VERSION "DNNBNNNYNNNNNNNNNNNNNNNNNNYYYNNNNNNNNNNNNN/4/%%%/4/'%**4NNN///"

NS_ :

BS_:

BU_: Hacker Engine Display Light

BO_ 3221225472 VECTOR__INDEPENDENT_SIG_MSG: 0 Vector__XXX
 SG_ ECUName : 0|8@1- (1,0) [0|0] "" Vector__XXX
 SG_ PrivateChallenge : 0|16@1+ (1,0) [0|0] "" Vector__XXX

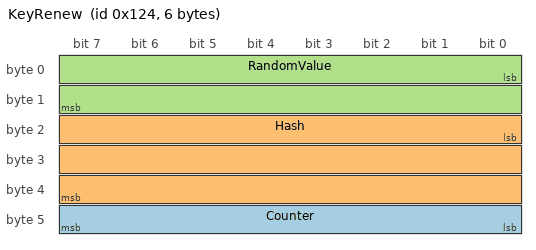
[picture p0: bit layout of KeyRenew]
BO_ 292 KeyRenew: 6 Vector__XXX
 SG_ Counter : 40|8@1+ (1,0) [0|0] "" Vector__XXX
 SG_ Hash : 16|24@1+ (1,0) [0|0] "" Vector__XXX
 SG_ RandomValue : 0|16@1+ (1,0) [0|0] "" Vector__XXX

BO_ 291 PublicID: 4 Vector__XXX
 SG_ PublicKey : 16|16@1+ (1,0) [0|0] ""  Engine,Display
 SG_ ECUName : 0|8@1- (1,0) [0|0] ""  Engine,Display

BO_ 531 BrakeState: 8 Hacker
 SG_ Hash : 40|24@1+ (1,0) [0|0] "" Vector__XXX
 SG_ BrakePressure : 0|15@1- (1,0) [0|0] ""  Display

BO_ 801 LightState: 1 Light
 SG_ FlashLight : 2|1@1+ (1,0) [0|1] ""  Display
 SG_ HeadLight : 0|1@1+ (1,0) [0|1] ""  Display

CM_ BO_ 3221225472 "This is a message for not used signals, created by Vector CANdb++ DBC OLE DB Provider.";
BA_DEF_ BU_  "ILUsed" ENUM  "Yes","No";
BA_DEF_ SG_  "GenSigSendType" ENUM  "Cyclic","OnWrite","OnWriteWithRepetition","OnChange","OnChangeWithRepetition","IfActive","IfActiveWithRepetition";
BA_DEF_ BO_  "GenMsgDelayTime" INT 1 1000;
BA_DEF_ BO_  "GenMsgCycleTime" INT 2 50000;
BA_DEF_ BO_  "GenMsgCycleTimeFast" INT 2 100000;
BA_DEF_ BO_  "GenMsgILSupport" ENUM  "No","Yes";
BA_DEF_ BU_  "NodeLayerModules" STRING ;
BA_DEF_DEF_  "ILUsed" "Yes";
BA_DEF_DEF_  "GenSigSendType" "Cyclic";
BA_DEF_DEF_  "GenMsgDelayTime" 1;
BA_DEF_DEF_  "GenMsgCycleTime" 2;
BA_DEF_DEF_  "GenMsgCycleTimeFast" 100;
BA_DEF_DEF_  "GenMsgILSupport" "Yes";
BA_DEF_DEF_  "NodeLayerModules" "CANoeILNLVector.dll";
BA_ "GenMsgCycleTime" BO_ 801 100;
BA_ "GenSigSendType" SG_ 801 HeadLight 3;
